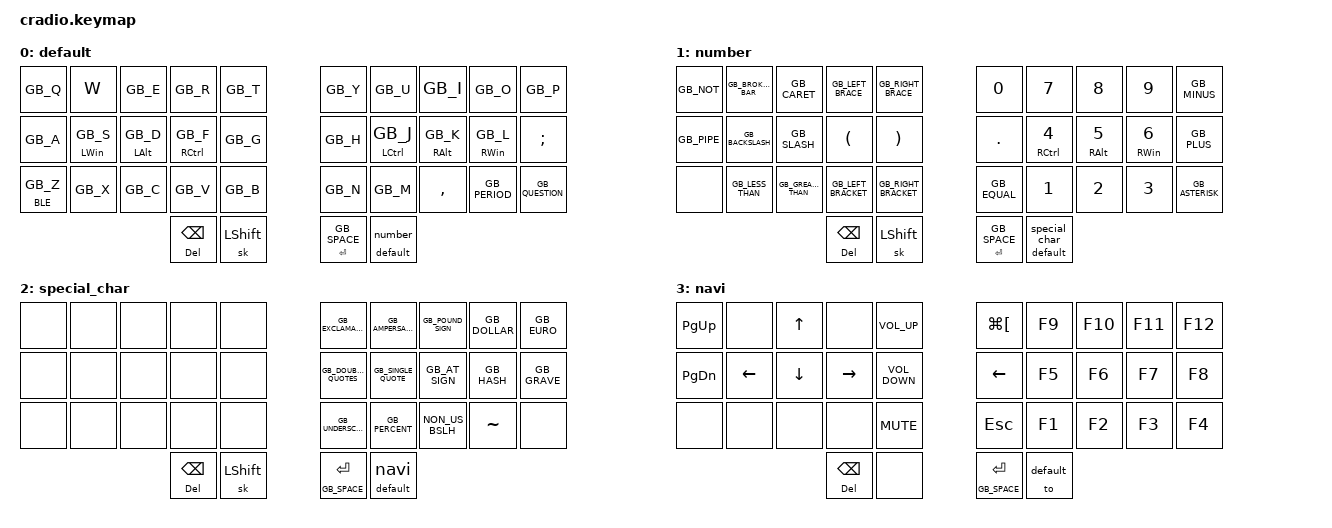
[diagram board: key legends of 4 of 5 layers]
/*
 * Copyright (c) 2020 The ZMK Contributors
 *
 * SPDX-License-Identifier: MIT
 */

#include <behaviors.dtsi>
#include <dt-bindings/zmk/bt.h>
#include <dt-bindings/zmk/keys.h>
#include <locale/keys_en_gb_extended.h>

#define default         0
#define number          1
#define special_char    2
#define navi            3
#define BLE             4

&mt {
    flavor = "tap-preferred";
    tapping_term_ms = <200>;
};

/ {
    behaviors {
        hm: homerow_mods {
            compatible = "zmk,behavior-hold-tap";
            label = "HOMEROW_MODS";
            #binding-cells = <2>;
            tapping-term-ms = <300>;
            quick_tap_ms = <150>;
            flavor = "tap-preferred";
            bindings = <&kp>, <&kp>;
        };

        td: tapdance {
            compatible = "zmk,behavior-hold-tap";
            label = "TAPDANCE";
            #binding-cells = <2>;
            tapping-term-ms = <300>;
            quick_tap_ms = <150>;
            flavor = "tap-preferred";
            bindings = <&kp>, <&kp>;
        };

        tl: temporary_layer_visible {
            compatible = "zmk,behavior-hold-tap";
            label = "TEMP_LAYER";
            #binding-cells = <2>;
            tapping-term-ms = <500>;
            quick_tap_ms = <150>;
            flavor = "hold-preferred";
            bindings = <&mo>, <&kp>;
        };

        lc: Layer_cycle {
            compatible = "zmk,behavior-hold-tap";
            label = "LAYER_CYCLE";
            #binding-cells = <2>;
            tapping-term-ms = <200>;
            quick_tap_ms = <0>;
            flavor = "tap-preferred";
            bindings = <&to>, <&to>;
        };
    };

    keymap {
        compatible = "zmk,keymap";

        default {
            bindings = <
&kp GB_Q            &kp W                   &kp GB_E                    &kp GB_R                    &kp GB_T                    &kp GB_Y                    &kp GB_U                &kp GB_I                    &kp GB_O                    &kp GB_P
&kp GB_A            &hm LEFT_WIN GB_S       &hm LALT GB_D               &hm RCTRL GB_F              &kp GB_G                    &kp GB_H                    &hm LCTRL GB_J          &hm RALT GB_K               &hm RIGHT_WIN GB_L          &kp SEMICOLON
&tl BLE GB_Z        &kp GB_X                &kp GB_C                    &kp GB_V                    &kp GB_B                    &kp GB_N                    &kp GB_M                &kp COMMA                   &kp GB_PERIOD               &kp GB_QUESTION
                                                                        &td DELETE BACKSPACE        &sk LSHIFT                  &td RETURN GB_SPACE           &lc default number
            >;
        };

        number {
            bindings = <
&kp GB_NOT          &kp GB_BROKEN_BAR       &kp GB_CARET                &kp GB_LEFT_BRACE           &kp GB_RIGHT_BRACE          &kp NUMBER_0                &kp NUMBER_7            &kp NUMBER_8                &kp NUMBER_9              &kp GB_MINUS
&kp GB_PIPE         &kp GB_BACKSLASH        &kp GB_SLASH                &kp LEFT_PARENTHESIS        &kp RIGHT_PARENTHESIS       &kp PERIOD                  &hm RCTRL NUMBER_4      &hm RALT NUMBER_5           &hm RIGHT_WIN NUMBER_6    &kp GB_PLUS
&none               &kp GB_LESS_THAN        &kp GB_GREATER_THAN         &kp GB_LEFT_BRACKET         &kp GB_RIGHT_BRACKET        &kp GB_EQUAL                &kp NUMBER_1            &kp NUMBER_2                &kp NUMBER_3              &kp GB_ASTERISK
                                                                        &td DELETE BACKSPACE        &sk LSHIFT                  &td RETURN GB_SPACE         &lc default special_char
            >;
        };

        special_char {
            bindings = <
&none               &none                   &none                       &none                       &none                       &kp GB_EXCLAMATION          &kp GB_AMPERSAND        &kp GB_POUND_SIGN           &kp GB_DOLLAR               &kp GB_EURO
&none               &none                   &none                       &none                       &none                       &kp GB_DOUBLE_QUOTES        &kp GB_SINGLE_QUOTE     &kp GB_AT_SIGN              &kp GB_HASH                 &kp GB_GRAVE
&none               &none                   &none                       &none                       &none                       &kp GB_UNDERSCORE           &kp GB_PERCENT          &kp NON_US_BSLH             &kp TILDE                   &none
                                                                        &td DELETE BACKSPACE        &sk LSHIFT                  &td GB_SPACE RETURN         &lc default navi
            >;
        };

        navi {
            bindings = <
&kp PAGE_UP        &none                   &kp UP_ARROW                 &none                       &kp K_VOLUME_UP             &kp LG(LBKT)                &kp F9                  &kp F10                     &kp F11                     &kp F12
&kp PAGE_DOWN      &kp LEFT_ARROW          &kp DOWN_ARROW               &kp RIGHT_ARROW             &kp K_VOLUME_DOWN           &kp LEFT                    &kp F5                  &kp F6                      &kp F7                      &kp F8
&none              &none                   &none                        &none                       &kp K_MUTE                  &kp ESC                     &kp F1                  &kp F2                      &kp F3                      &kp F4
                                                                        &td DELETE BACKSPACE        &none                       &td GB_SPACE RETURN         &to default
            >;
        };

        BLE {
            bindings = <
&none               &bt BT_CLR              &bt BT_CLR_ALL              &none                       &none                       &none                       &none                   &none                       &none                       &none
&none               &bt BT_DISC 0           &bt BT_DISC 1               &bt BT_DISC 2               &bt BT_DISC 3               &none                       &none                   &none                       &none                       &none
&none               &bt BT_SEL 0            &bt BT_SEL 1                &bt BT_SEL 2                &bt BT_SEL 3                &none                       &none                   &none                       &none                       &none  
             >;
        };
    };
};
